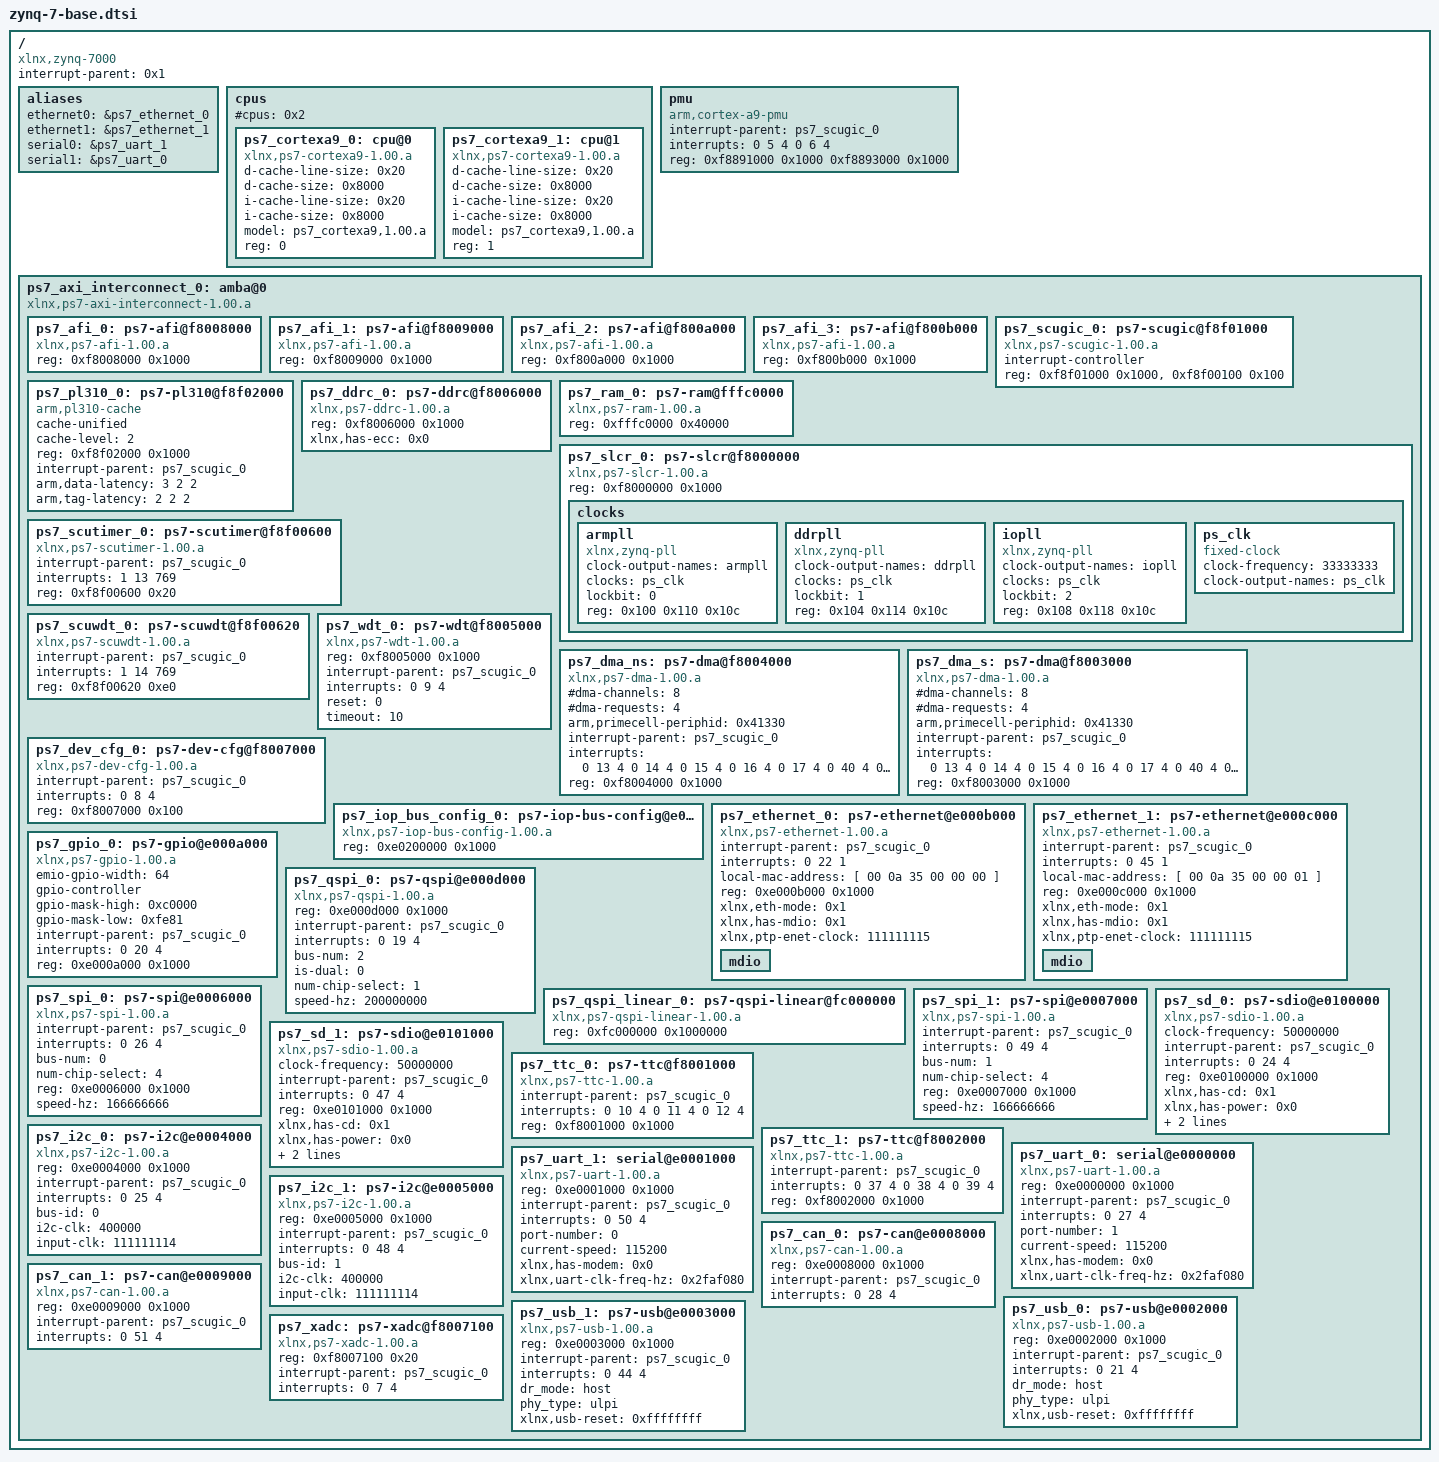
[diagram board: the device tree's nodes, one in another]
/*
 * Zynq 7000 Base Device Tree (System Peripherals and Configuration)
 *
 * To use this base include it in the dts/dtsi which relies on it.
 *     /dts-v1/;
 *     /include/ "zynq-7-base.dtsi"
 *     / {
 *     ...
 *
 * In order to configure your board specific configuration of the Zynq platform,
 * or to configure additional devices attached to Zynq peripherals use the base
 * include and override properties, add subnodes or disable existing
 * peripherals.
 *
 * To disable or invalidate an existing Zynq peripheral:
 *     ...
 *         ps7_axi_interconnect_0: amba@0 {
 *             ps7_usb_1: ps7-usb@e0003000 { compatible = "invalid"; };
 *         } ;
 *     ...
 *
 * To override a property of an existing peripheral:
 *     ...
 *         ps7_axi_interconnect_0: amba@0 {
 *             ps7_usb_0: ps7-usb@e0002000 {
 *                 dr_mode = "device";
 *             } ;
 *         } ;
 *     ...
 *
 * To add an additional subnode (e.g. a device attached to a bus) to an existing
 * peripheral:
 *     ...
 *         ps7_axi_interconnect_0: amba@0 {
 *             ps7_ethernet_0: ps7-ethernet@e000b000 {
 *                 mdio {
 *                     phy0: phy@7 {
 *                         device_type = "ethernet-phy";
 *                         reg = <7>;
 *                     } ;
 *                 } ;
 *             } ;
 *         } ;
 *     ...
 *
 * For more details, or for reference please refer to device trees in the
 * meta-xilinx layer that use this base tree.
 */

/ {
	#address-cells = <0x1>;
	#size-cells = <0x1>;
	compatible = "xlnx,zynq-7000", "xlnx,zynq-zc770";
	interrupt-parent = <0x1>;
	aliases {
		ethernet0 = &ps7_ethernet_0;
		ethernet1 = &ps7_ethernet_1;
		serial0 = &ps7_uart_1;
		serial1 = &ps7_uart_0;
	} ;
	cpus {
		#address-cells = <1>;
		#cpus = <0x2>;
		#size-cells = <0>;
		ps7_cortexa9_0: cpu@0 {
			compatible = "xlnx,ps7-cortexa9-1.00.a";
			d-cache-line-size = <0x20>;
			d-cache-size = <0x8000>;
			device_type = "cpu";
			i-cache-line-size = <0x20>;
			i-cache-size = <0x8000>;
			model = "ps7_cortexa9,1.00.a";
			reg = <0>;
		} ;
		ps7_cortexa9_1: cpu@1 {
			compatible = "xlnx,ps7-cortexa9-1.00.a";
			d-cache-line-size = <0x20>;
			d-cache-size = <0x8000>;
			device_type = "cpu";
			i-cache-line-size = <0x20>;
			i-cache-size = <0x8000>;
			model = "ps7_cortexa9,1.00.a";
			reg = <1>;
		} ;
	} ;
	pmu {
		compatible = "arm,cortex-a9-pmu";
		interrupt-parent = <&ps7_scugic_0>;
		interrupts = < 0 5 4 0 6 4 >;
		reg = < 0xf8891000 0x1000 0xf8893000 0x1000 >;
	} ;
	ps7_axi_interconnect_0: amba@0 {
		#address-cells = <1>;
		#size-cells = <1>;
		compatible = "xlnx,ps7-axi-interconnect-1.00.a", "simple-bus";
		ranges ;
		ps7_afi_0: ps7-afi@f8008000 {
			compatible = "xlnx,ps7-afi-1.00.a";
			reg = < 0xf8008000 0x1000 >;
		} ;
		ps7_afi_1: ps7-afi@f8009000 {
			compatible = "xlnx,ps7-afi-1.00.a";
			reg = < 0xf8009000 0x1000 >;
		} ;
		ps7_afi_2: ps7-afi@f800a000 {
			compatible = "xlnx,ps7-afi-1.00.a";
			reg = < 0xf800a000 0x1000 >;
		} ;
		ps7_afi_3: ps7-afi@f800b000 {
			compatible = "xlnx,ps7-afi-1.00.a";
			reg = < 0xf800b000 0x1000 >;
		} ;
		ps7_scugic_0: ps7-scugic@f8f01000 {
			#interrupt-cells = < 3 >;
			compatible = "xlnx,ps7-scugic-1.00.a", "arm,cortex-a9-gic", "arm,gic";
			interrupt-controller ;
			reg = < 0xf8f01000 0x1000 >, < 0xf8f00100 0x100 >;
		} ;
		ps7_pl310_0: ps7-pl310@f8f02000 {
			compatible = "arm,pl310-cache";
			cache-unified;
			cache-level = <2>;
			reg = <0xf8f02000 0x1000>;
			interrupt-parent = <&ps7_scugic_0>;
			arm,data-latency = <3 2 2>;
			arm,tag-latency = <2 2 2>;
		} ;
		ps7_ddrc_0: ps7-ddrc@f8006000 {
			compatible = "xlnx,ps7-ddrc-1.00.a", "xlnx,ps7-ddrc";
			reg = < 0xf8006000 0x1000 >;
			xlnx,has-ecc = <0x0>;
		} ;
		ps7_ram_0: ps7-ram@fffc0000 {
			compatible = "xlnx,ps7-ram-1.00.a", "xlnx,ps7-ocm";
			reg = < 0xfffc0000 0x40000 >;
		} ;
		ps7_slcr_0: ps7-slcr@f8000000 {
			compatible = "xlnx,ps7-slcr-1.00.a", "xlnx,zynq-slcr";
			reg = < 0xf8000000 0x1000 >;
			clocks {
				#address-cells = <1>;
				#size-cells = <0>;
				armpll: armpll {
					#clock-cells = <0>;
					clock-output-names = "armpll";
					clocks = <&ps_clk>;
					compatible = "xlnx,zynq-pll";
					lockbit = <0>;
					reg = < 0x100 0x110 0x10c >;
				} ;
				ddrpll: ddrpll {
					#clock-cells = <0>;
					clock-output-names = "ddrpll";
					clocks = <&ps_clk>;
					compatible = "xlnx,zynq-pll";
					lockbit = <1>;
					reg = < 0x104 0x114 0x10c >;
				} ;
				iopll: iopll {
					#clock-cells = <0>;
					clock-output-names = "iopll";
					clocks = <&ps_clk>;
					compatible = "xlnx,zynq-pll";
					lockbit = <2>;
					reg = < 0x108 0x118 0x10c >;
				} ;
				ps_clk: ps_clk {
					#clock-cells = <0>;
					clock-frequency = <33333333>;
					clock-output-names = "ps_clk";
					compatible = "fixed-clock";
				} ;
			} ;
		} ;
		ps7_scutimer_0: ps7-scutimer@f8f00600 {
			compatible = "xlnx,ps7-scutimer-1.00.a", "arm,cortex-a9-twd-timer";
			interrupt-parent = <&ps7_scugic_0>;
			interrupts = < 1 13 769 >;
			reg = < 0xf8f00600 0x20 >;
		} ;
		ps7_scuwdt_0: ps7-scuwdt@f8f00620 {
			compatible = "xlnx,ps7-scuwdt-1.00.a";
			device_type = "watchdog";
			interrupt-parent = <&ps7_scugic_0>;
			interrupts = < 1 14 769 >;
			reg = < 0xf8f00620 0xe0 >;
		} ;
		ps7_wdt_0: ps7-wdt@f8005000 {
			compatible = "xlnx,ps7-wdt-1.00.a";
			reg = < 0xf8005000 0x1000 >;
			interrupt-parent = <&ps7_scugic_0>;
			interrupts = < 0 9 4 >;
			device_type = "watchdog";
			reset = <0>;
			timeout = <10>;
		} ;
		ps7_dma_ns: ps7-dma@f8004000 {
			#dma-cells = <1>;
			#dma-channels = <8>;
			#dma-requests = <4>;
			arm,primecell-periphid = <0x41330>;
			compatible = "xlnx,ps7-dma-1.00.a", "arm,pl330";
			interrupt-parent = <&ps7_scugic_0>;
			interrupts = < 0 13 4 0 14 4 0 15 4 0 16 4 0 17 4 0 40 4 0 41 4 0 42 4 0 43 4 >;
			reg = < 0xf8004000 0x1000 >;
		} ;
		ps7_dma_s: ps7-dma@f8003000 {
			#dma-cells = <1>;
			#dma-channels = <8>;
			#dma-requests = <4>;
			arm,primecell-periphid = <0x41330>;
			compatible = "xlnx,ps7-dma-1.00.a", "arm,primecell", "arm,pl330";
			interrupt-parent = <&ps7_scugic_0>;
			interrupts = < 0 13 4 0 14 4 0 15 4 0 16 4 0 17 4 0 40 4 0 41 4 0 42 4 0 43 4 >;
			reg = < 0xf8003000 0x1000 >;
		} ;
		ps7_dev_cfg_0: ps7-dev-cfg@f8007000 {
			compatible = "xlnx,ps7-dev-cfg-1.00.a";
			interrupt-parent = <&ps7_scugic_0>;
			interrupts = < 0 8 4 >;
			reg = < 0xf8007000 0x100 >;
		} ;
		ps7_iop_bus_config_0: ps7-iop-bus-config@e0200000 {
			compatible = "xlnx,ps7-iop-bus-config-1.00.a";
			reg = < 0xe0200000 0x1000 >;
		} ;

		/* ========= Peripherals ========= */

		ps7_ethernet_0: ps7-ethernet@e000b000 {
			#address-cells = <1>;
			#size-cells = <0>;
			compatible = "xlnx,ps7-ethernet-1.00.a";
			interrupt-parent = <&ps7_scugic_0>;
			interrupts = < 0 22 1 >;
			local-mac-address = [ 00 0a 35 00 00 00 ];
			reg = < 0xe000b000 0x1000 >;
			xlnx,eth-mode = <0x1>;
			xlnx,has-mdio = <0x1>;
			xlnx,ptp-enet-clock = <111111115>;
			mdio {
				#address-cells = <1>;
				#size-cells = <0>;
			} ;
		} ;
		ps7_ethernet_1: ps7-ethernet@e000c000 {
			#address-cells = <1>;
			#size-cells = <0>;
			compatible = "xlnx,ps7-ethernet-1.00.a";
			interrupt-parent = <&ps7_scugic_0>;
			interrupts = < 0 45 1 >;
			local-mac-address = [ 00 0a 35 00 00 01 ];
			reg = < 0xe000c000 0x1000 >;
			xlnx,eth-mode = <0x1>;
			xlnx,has-mdio = <0x1>;
			xlnx,ptp-enet-clock = <111111115>;
			mdio {
				#address-cells = <1>;
				#size-cells = <0>;
			} ;
		} ;

		ps7_gpio_0: ps7-gpio@e000a000 {
			#gpio-cells = <2>;
			compatible = "xlnx,ps7-gpio-1.00.a";
			emio-gpio-width = <64>;
			gpio-controller ;
			gpio-mask-high = <0xc0000>;
			gpio-mask-low = <0xfe81>;
			interrupt-parent = <&ps7_scugic_0>;
			interrupts = < 0 20 4 >;
			reg = < 0xe000a000 0x1000 >;
		} ;

		ps7_qspi_0: ps7-qspi@e000d000 {
			compatible = "xlnx,ps7-qspi-1.00.a";
			reg = < 0xe000d000 0x1000 >;
			interrupt-parent = <&ps7_scugic_0>;
			interrupts = < 0 19 4 >;
			bus-num = <2>;
			is-dual = <0>;
			num-chip-select = <1>;
			speed-hz = <200000000>;
			#address-cells = <1>;
			#size-cells = <0>;
		} ;
		ps7_qspi_linear_0: ps7-qspi-linear@fc000000 {
			compatible = "xlnx,ps7-qspi-linear-1.00.a";
			reg = < 0xfc000000 0x1000000 >;
		} ;

		ps7_spi_0: ps7-spi@e0006000 {
			compatible = "xlnx,ps7-spi-1.00.a";
			interrupt-parent = <&ps7_scugic_0>;
			interrupts = < 0 26 4 >;
			bus-num = <0>;
			num-chip-select = <4>;
			reg = < 0xe0006000 0x1000 >;
			speed-hz = <166666666>;
			#address-cells = <1>;
			#size-cells = <0>;
		} ;
		ps7_spi_1: ps7-spi@e0007000 {
			compatible = "xlnx,ps7-spi-1.00.a";
			interrupt-parent = <&ps7_scugic_0>;
			interrupts = < 0 49 4 >;
			bus-num = <1>;
			num-chip-select = <4>;
			reg = < 0xe0007000 0x1000 >;
			speed-hz = <166666666>;
			#address-cells = <1>;
			#size-cells = <0>;
		} ;

		ps7_sd_0: ps7-sdio@e0100000 {
			clock-frequency = <50000000>;
			compatible = "xlnx,ps7-sdio-1.00.a", "generic-sdhci";
			interrupt-parent = <&ps7_scugic_0>;
			interrupts = < 0 24 4 >;
			reg = < 0xe0100000 0x1000 >;
			xlnx,has-cd = <0x1>;
			xlnx,has-power = <0x0>;
			xlnx,has-wp = <0x1>;
			xlnx,sdio-clk-freq-hz = <0x2faf080>;
		} ;
		ps7_sd_1: ps7-sdio@e0101000 {
			clock-frequency = <50000000>;
			compatible = "xlnx,ps7-sdio-1.00.a", "generic-sdhci";
			interrupt-parent = <&ps7_scugic_0>;
			interrupts = < 0 47 4 >;
			reg = < 0xe0101000 0x1000 >;
			xlnx,has-cd = <0x1>;
			xlnx,has-power = <0x0>;
			xlnx,has-wp = <0x1>;
			xlnx,sdio-clk-freq-hz = <0x2faf080>;
		} ;

		ps7_ttc_0: ps7-ttc@f8001000 {
			compatible = "xlnx,ps7-ttc-1.00.a";
			interrupt-parent = <&ps7_scugic_0>;
			interrupts = < 0 10 4 0 11 4 0 12 4 >;
			reg = < 0xf8001000 0x1000 >;
		} ;
		ps7_ttc_1: ps7-ttc@f8002000 {
			compatible = "xlnx,ps7-ttc-1.00.a";
			interrupt-parent = <&ps7_scugic_0>;
			interrupts = < 0 37 4 0 38 4 0 39 4 >;
			reg = < 0xf8002000 0x1000 >;
		} ;

		ps7_uart_0: serial@e0000000 {
			compatible = "xlnx,ps7-uart-1.00.a", "xlnx,xuartps";
			reg = < 0xe0000000 0x1000 >;
			interrupt-parent = <&ps7_scugic_0>;
			interrupts = < 0 27 4 >;
			device_type = "serial";
			port-number = <1>;
			current-speed = <115200>;
			xlnx,has-modem = <0x0>;
			xlnx,uart-clk-freq-hz = <0x2faf080>;
		} ;
		ps7_uart_1: serial@e0001000 {
			compatible = "xlnx,ps7-uart-1.00.a", "xlnx,xuartps";
			reg = < 0xe0001000 0x1000 >;
			interrupt-parent = <&ps7_scugic_0>;
			interrupts = < 0 50 4 >;
			device_type = "serial";
			port-number = <0>;
			current-speed = <115200>;
			xlnx,has-modem = <0x0>;
			xlnx,uart-clk-freq-hz = <0x2faf080>;
		} ;

		ps7_i2c_0: ps7-i2c@e0004000 {
			compatible = "xlnx,ps7-i2c-1.00.a";
			reg = < 0xe0004000 0x1000 >;
			interrupt-parent = <&ps7_scugic_0>;
			interrupts = < 0 25 4 >;
			bus-id = <0>;
			i2c-clk = <400000>;
			input-clk = <111111114>;
			#address-cells = <1>;
			#size-cells = <0>;
		} ;
		ps7_i2c_1: ps7-i2c@e0005000 {
			compatible = "xlnx,ps7-i2c-1.00.a";
			reg = < 0xe0005000 0x1000 >;
			interrupt-parent = <&ps7_scugic_0>;
			interrupts = < 0 48 4 >;
			bus-id = <1>;
			i2c-clk = <400000>;
			input-clk = <111111114>;
			#address-cells = <1>;
			#size-cells = <0>;
		} ;

		ps7_can_0: ps7-can@e0008000 {
			compatible = "xlnx,ps7-can-1.00.a";
			reg = < 0xe0008000 0x1000 >;
			interrupt-parent = <&ps7_scugic_0>;
			interrupts = < 0 28 4 >;
		} ;
		ps7_can_1: ps7-can@e0009000 {
			compatible = "xlnx,ps7-can-1.00.a";
			reg = < 0xe0009000 0x1000 >;
			interrupt-parent = <&ps7_scugic_0>;
			interrupts = < 0 51 4 >;
		} ;

		ps7_usb_0: ps7-usb@e0002000 {
			compatible = "xlnx,ps7-usb-1.00.a";
			reg = < 0xe0002000 0x1000 >;
			interrupt-parent = <&ps7_scugic_0>;
			interrupts = < 0 21 4 >;
			dr_mode = "host";
			phy_type = "ulpi";
			xlnx,usb-reset = <0xffffffff>;
		} ;
		ps7_usb_1: ps7-usb@e0003000 {
			compatible = "xlnx,ps7-usb-1.00.a";
			reg = < 0xe0003000 0x1000 >;
			interrupt-parent = <&ps7_scugic_0>;
			interrupts = < 0 44 4 >;
			dr_mode = "host";
			phy_type = "ulpi";
			xlnx,usb-reset = <0xffffffff>;
		} ;

		ps7_xadc: ps7-xadc@f8007100 {
			compatible = "xlnx,ps7-xadc-1.00.a";
			reg = < 0xf8007100 0x20 >;
			interrupt-parent = <&ps7_scugic_0>;
			interrupts = < 0 7 4 >;
		} ;
	} ;
} ;
